# CTRL_MODULE_CORE_PAD register map
Vendor: Texas Instruments
Peripheral module from a debugger description file (folder omap5430_ES2_PUBLIC).
Registers are 32-bit, access per field, reset 0x10F010F unless marked. A register's access mark holds for its fields unless they carry their own. Offsets are as the file gives them; lines under a group give offsets from that group; [hi:lo] are bit positions; {n}, {i} and the like mark numbered series; 'fields as' and 'values as' point back to an identical list; <NAME> marks a mode.

## CTRL_MODULE_CORE_PAD (part 1 of 7)
0x00 CONTROL_CORE_PAD_REVISION ro reset not defined — Control module revision identifier Access conditions. Read: unrestricted, Write: unrestricted
  [31:0] REVISON — IP Revision enum=hl_scheme . enum=legacy_scheme .
0x04 CONTROL_CORE_PAD_HWINFO ro reset 0x0 — Information about the IP module hardware configuration i.e. typically the module HDL generics (if any). Access conditions. Read: unrestricted, Write: unrestricted
  [31:0] IP_HWINFO — IP-module dependent
0x10 CONTROL_CORE_PAD_SYSCONFIG reset 0x8 — Access conditions. Read: unrestricted, Write: unrestricted
  [3:2] IP_SYSCONFIG_IDLEMODE rw — RESERVED (not used).
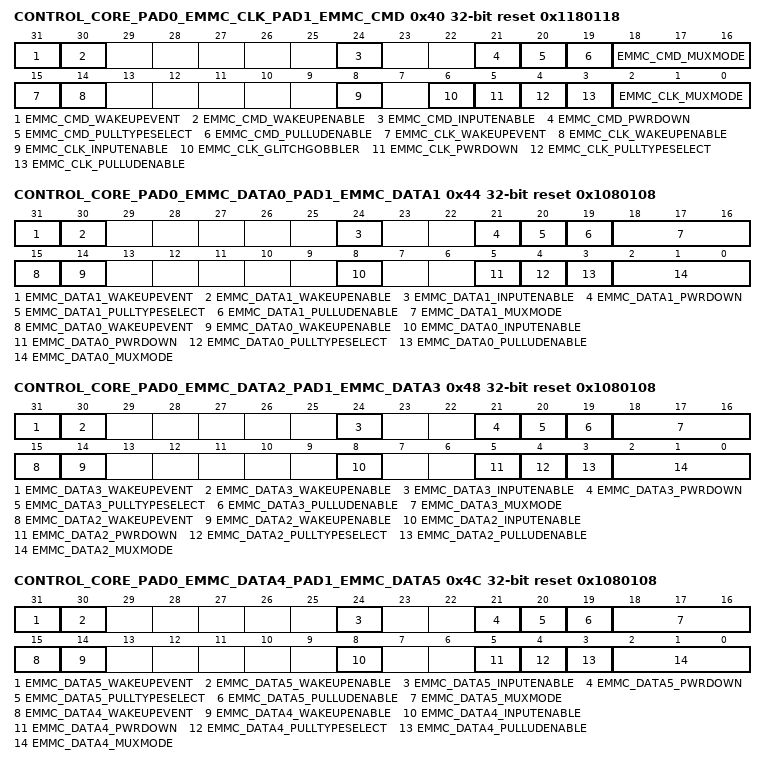
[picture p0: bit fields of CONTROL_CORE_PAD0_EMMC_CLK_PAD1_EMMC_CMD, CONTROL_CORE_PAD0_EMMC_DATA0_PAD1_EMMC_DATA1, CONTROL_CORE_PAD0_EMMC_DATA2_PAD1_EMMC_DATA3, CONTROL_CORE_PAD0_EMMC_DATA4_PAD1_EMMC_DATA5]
0x40 CONTROL_CORE_PAD0_EMMC_CLK_PAD1_EMMC_CMD reset 0x1180118 — Register control for Pads emmc_clk and emmc_cmd Access conditions. Read: unrestricted, Write: unrestricted)
  [31] EMMC_CMD_WAKEUPEVENT ro — Pad_x wake-up event status latched in the IO
    1=WakeUp (A wake-up event occurred); 0=No wake-up event occurred
  [30] EMMC_CMD_WAKEUPENABLE rw — Input pad wake-up enable
    0=DetectLow (wake-up detection is disabled); 1=DetectLowHigh (wake-up detection is enabled)
  [24] EMMC_CMD_INPUTENABLE rw — Input enable value for pad emmc_cmd
    0=InputBufferDisabled (Input buffer of IO cell is disabled); 1=InputBufferEnabled (Input buffer of IO cell is enabled)
  [21] EMMC_CMD_PWRDOWN rw — Power Down setting for pad emmc_cmd
    0=PwrDownDisabled (IO cell power is ON); 1=PwrDownEnabled (IO cell power is OFF)
  [20] EMMC_CMD_PULLTYPESELECT rw — Pull-Up/Down selection for pad emmc_cmd
    0=Pull-Down selected; 1=Pull-Up selected
  [19] EMMC_CMD_PULLUDENABLE rw — Pull-Up/Down enable for pad emmc_cmd
    0=PullDisabled (Pull-Up/Down disabled); 1=PullEnabled (Pull-Up/Down enabled)
  [18:16] EMMC_CMD_MUXMODE rw — Functional multiplexing selection for pad emmc_cmd
    0=SEL_EMMC_CMD (Select emmc_cmd); 7=SEL_SAFE_MODE_CORE1 (Select safe_mode_core1); 6=SEL_GPIO2_47 (Select gpio2_47)
  [15] EMMC_CLK_WAKEUPEVENT ro — Pad_x wake-up event status latched in the IO
    values as EMMC_CMD_WAKEUPEVENT
  [14] EMMC_CLK_WAKEUPENABLE rw — Input pad wake-up enable
    values as EMMC_CMD_WAKEUPENABLE
  [8] EMMC_CLK_INPUTENABLE rw — Input enable value for pad emmc_clk
    values as EMMC_CMD_INPUTENABLE
  [6] EMMC_CLK_GLITCHGOBBLER rw — Glitch Gobbler setting for pad emmc_clk
    0=GlitchGobblerDisabled (IO do not Filter glitch from outside); 1=GlitchGobblerEnabled (IO Filter glitch from outside)
  [5] EMMC_CLK_PWRDOWN rw — Power Down setting for pad emmc_clk
    values as EMMC_CMD_PWRDOWN
  [4] EMMC_CLK_PULLTYPESELECT rw — Pull-Up/Down selection for pad emmc_clk
    0=Pull-Down selected; 1=Pull-Up selected
  [3] EMMC_CLK_PULLUDENABLE rw — Pull-Up/Down enable for pad emmc_clk
    values as EMMC_CMD_PULLUDENABLE
  [2:0] EMMC_CLK_MUXMODE rw — Functional multiplexing selection for pad emmc_clk
    0=SEL_EMMC_CLK (Select emmc_clk); 7=SEL_SAFE_MODE_CORE0 (Select safe_mode_core0); 6=SEL_GPIO2_46 (Select gpio2_46)
0x44 CONTROL_CORE_PAD0_EMMC_DATA0_PAD1_EMMC_DATA1 reset 0x1080108 — Register control for Pads emmc_data0 and emmc_data1 Access conditions. Read: unrestricted, Write: unrestricted
  [31] EMMC_DATA1_WAKEUPEVENT ro — Pad_x wake-up event status latched in the IO
    values as CONTROL_CORE_PAD0_EMMC_CLK_PAD1_EMMC_CMD.EMMC_CMD_WAKEUPEVENT
  [30] EMMC_DATA1_WAKEUPENABLE rw — Input pad wake-up enable
    values as CONTROL_CORE_PAD0_EMMC_CLK_PAD1_EMMC_CMD.EMMC_CMD_WAKEUPENABLE
  [24] EMMC_DATA1_INPUTENABLE rw — Input enable value for pad emmc_data1
    values as CONTROL_CORE_PAD0_EMMC_CLK_PAD1_EMMC_CMD.EMMC_CMD_INPUTENABLE
  [21] EMMC_DATA1_PWRDOWN rw — Power Down setting for pad emmc_data1
    values as CONTROL_CORE_PAD0_EMMC_CLK_PAD1_EMMC_CMD.EMMC_CMD_PWRDOWN
  [20] EMMC_DATA1_PULLTYPESELECT rw — Pull-Up/Down selection for pad emmc_data1
    0=Pull-Down selected; 1=Pull-Up selected
  [19] EMMC_DATA1_PULLUDENABLE rw — Pull-Up/Down enable for pad emmc_data1
    values as CONTROL_CORE_PAD0_EMMC_CLK_PAD1_EMMC_CMD.EMMC_CMD_PULLUDENABLE
  [18:16] EMMC_DATA1_MUXMODE rw — Functional multiplexing selection for pad emmc_data1
    0=SEL_EMMC_DATA1 (Select emmc_data1); 7=SEL_SAFE_MODE_CORE3 (Select safe_mode_core3); 6=SEL_GPIO2_49 (Select gpio2_49)
  [15] EMMC_DATA0_WAKEUPEVENT ro — Pad_x wake-up event status latched in the IO
    values as CONTROL_CORE_PAD0_EMMC_CLK_PAD1_EMMC_CMD.EMMC_CMD_WAKEUPEVENT
  [14] EMMC_DATA0_WAKEUPENABLE rw — Input pad wake-up enable
    values as CONTROL_CORE_PAD0_EMMC_CLK_PAD1_EMMC_CMD.EMMC_CMD_WAKEUPENABLE
  [8] EMMC_DATA0_INPUTENABLE rw — Input enable value for pad emmc_data0
    values as CONTROL_CORE_PAD0_EMMC_CLK_PAD1_EMMC_CMD.EMMC_CMD_INPUTENABLE
  [5] EMMC_DATA0_PWRDOWN rw — Power Down setting for pad emmc_data0
    values as CONTROL_CORE_PAD0_EMMC_CLK_PAD1_EMMC_CMD.EMMC_CMD_PWRDOWN
  [4] EMMC_DATA0_PULLTYPESELECT rw — Pull-Up/Down selection for pad emmc_data0
    0=Pull-Down selected; 1=Pull-Up selected
  [3] EMMC_DATA0_PULLUDENABLE rw — Pull-Up/Down enable for pad emmc_data0
    values as CONTROL_CORE_PAD0_EMMC_CLK_PAD1_EMMC_CMD.EMMC_CMD_PULLUDENABLE
  [2:0] EMMC_DATA0_MUXMODE rw — Functional multiplexing selection for pad emmc_data0
    0=SEL_EMMC_DATA0 (Select emmc_data0); 7=SEL_SAFE_MODE_CORE2 (Select safe_mode_core2); 6=SEL_GPIO2_48 (Select gpio2_48)
0x48 CONTROL_CORE_PAD0_EMMC_DATA2_PAD1_EMMC_DATA3 reset 0x1080108 — Register control for Pads emmc_data2 and emmc_data3 Access conditions. Read: unrestricted, Write: unrestricted
  [31] EMMC_DATA3_WAKEUPEVENT ro — Pad_x wake-up event status latched in the IO
    values as CONTROL_CORE_PAD0_EMMC_CLK_PAD1_EMMC_CMD.EMMC_CMD_WAKEUPEVENT
  [30] EMMC_DATA3_WAKEUPENABLE rw — Input pad wake-up enable
    values as CONTROL_CORE_PAD0_EMMC_CLK_PAD1_EMMC_CMD.EMMC_CMD_WAKEUPENABLE
  [24] EMMC_DATA3_INPUTENABLE rw — Input enable value for pad emmc_data3
    values as CONTROL_CORE_PAD0_EMMC_CLK_PAD1_EMMC_CMD.EMMC_CMD_INPUTENABLE
  [21] EMMC_DATA3_PWRDOWN rw — Power Down setting for pad emmc_data3
    values as CONTROL_CORE_PAD0_EMMC_CLK_PAD1_EMMC_CMD.EMMC_CMD_PWRDOWN
  [20] EMMC_DATA3_PULLTYPESELECT rw — Pull-Up/Down selection for pad emmc_data3
    0=Pull-Down selected; 1=Pull-Up selected
  [19] EMMC_DATA3_PULLUDENABLE rw — Pull-Up/Down enable for pad emmc_data3
    values as CONTROL_CORE_PAD0_EMMC_CLK_PAD1_EMMC_CMD.EMMC_CMD_PULLUDENABLE
  [18:16] EMMC_DATA3_MUXMODE rw — Functional multiplexing selection for pad emmc_data3
    0=SEL_EMMC_DATA3 (Select emmc_data3); 7=SEL_SAFE_MODE_CORE5 (Select safe_mode_core5); 6=SEL_GPIO2_51 (Select gpio2_51)
  [15] EMMC_DATA2_WAKEUPEVENT ro — Pad_x wake-up event status latched in the IO
    values as CONTROL_CORE_PAD0_EMMC_CLK_PAD1_EMMC_CMD.EMMC_CMD_WAKEUPEVENT
  [14] EMMC_DATA2_WAKEUPENABLE rw — Input pad wake-up enable
    values as CONTROL_CORE_PAD0_EMMC_CLK_PAD1_EMMC_CMD.EMMC_CMD_WAKEUPENABLE
  [8] EMMC_DATA2_INPUTENABLE rw — Input enable value for pad emmc_data2
    values as CONTROL_CORE_PAD0_EMMC_CLK_PAD1_EMMC_CMD.EMMC_CMD_INPUTENABLE
  [5] EMMC_DATA2_PWRDOWN rw — Power Down setting for pad emmc_data2
    values as CONTROL_CORE_PAD0_EMMC_CLK_PAD1_EMMC_CMD.EMMC_CMD_PWRDOWN
  [4] EMMC_DATA2_PULLTYPESELECT rw — Pull-Up/Down selection for pad emmc_data2
    0=Pull-Down selected; 1=Pull-Up selected
  [3] EMMC_DATA2_PULLUDENABLE rw — Pull-Up/Down enable for pad emmc_data2
    values as CONTROL_CORE_PAD0_EMMC_CLK_PAD1_EMMC_CMD.EMMC_CMD_PULLUDENABLE
  [2:0] EMMC_DATA2_MUXMODE rw — Functional multiplexing selection for pad emmc_data2
    0=SEL_EMMC_DATA2 (Select emmc_data2); 7=SEL_SAFE_MODE_CORE4 (Select safe_mode_core4); 6=SEL_GPIO2_50 (Select gpio2_50)
0x4C CONTROL_CORE_PAD0_EMMC_DATA4_PAD1_EMMC_DATA5 reset 0x1080108 — Register control for Pads emmc_data4 and emmc_data5 Access conditions. Read: unrestricted, Write: unrestricted
  [31] EMMC_DATA5_WAKEUPEVENT ro — Pad_x wake-up event status latched in the IO
    values as CONTROL_CORE_PAD0_EMMC_CLK_PAD1_EMMC_CMD.EMMC_CMD_WAKEUPEVENT
  [30] EMMC_DATA5_WAKEUPENABLE rw — Input pad wake-up enable
    values as CONTROL_CORE_PAD0_EMMC_CLK_PAD1_EMMC_CMD.EMMC_CMD_WAKEUPENABLE
  [24] EMMC_DATA5_INPUTENABLE rw — Input enable value for pad emmc_data5
    values as CONTROL_CORE_PAD0_EMMC_CLK_PAD1_EMMC_CMD.EMMC_CMD_INPUTENABLE
  [21] EMMC_DATA5_PWRDOWN rw — Power Down setting for pad emmc_data5
    values as CONTROL_CORE_PAD0_EMMC_CLK_PAD1_EMMC_CMD.EMMC_CMD_PWRDOWN
  [20] EMMC_DATA5_PULLTYPESELECT rw — Pull-Up/Down selection for pad emmc_data5
    0=Pull-Down selected; 1=Pull-Up selected
  [19] EMMC_DATA5_PULLUDENABLE rw — Pull-Up/Down enable for pad emmc_data5
    values as CONTROL_CORE_PAD0_EMMC_CLK_PAD1_EMMC_CMD.EMMC_CMD_PULLUDENABLE
  [18:16] EMMC_DATA5_MUXMODE rw — Functional multiplexing selection for pad emmc_data5
    0=SEL_EMMC_DATA5 (Select emmc_data5); 7=SEL_SAFE_MODE_CORE7 (Select safe_mode_core7); 6=SEL_GPIO2_53 (Select gpio2_53)
  [15] EMMC_DATA4_WAKEUPEVENT ro — Pad_x wake-up event status latched in the IO
    values as CONTROL_CORE_PAD0_EMMC_CLK_PAD1_EMMC_CMD.EMMC_CMD_WAKEUPEVENT
  [14] EMMC_DATA4_WAKEUPENABLE rw — Input pad wake-up enable
    values as CONTROL_CORE_PAD0_EMMC_CLK_PAD1_EMMC_CMD.EMMC_CMD_WAKEUPENABLE
  [8] EMMC_DATA4_INPUTENABLE rw — Input enable value for pad emmc_data4
    values as CONTROL_CORE_PAD0_EMMC_CLK_PAD1_EMMC_CMD.EMMC_CMD_INPUTENABLE
  [5] EMMC_DATA4_PWRDOWN rw — Power Down setting for pad emmc_data4
    values as CONTROL_CORE_PAD0_EMMC_CLK_PAD1_EMMC_CMD.EMMC_CMD_PWRDOWN
  [4] EMMC_DATA4_PULLTYPESELECT rw — Pull-Up/Down selection for pad emmc_data4
    0=Pull-Down selected; 1=Pull-Up selected
  [3] EMMC_DATA4_PULLUDENABLE rw — Pull-Up/Down enable for pad emmc_data4
    values as CONTROL_CORE_PAD0_EMMC_CLK_PAD1_EMMC_CMD.EMMC_CMD_PULLUDENABLE
  [2:0] EMMC_DATA4_MUXMODE rw — Functional multiplexing selection for pad emmc_data4
    0=SEL_EMMC_DATA4 (Select emmc_data4); 7=SEL_SAFE_MODE_CORE6 (Select safe_mode_core6); 6=SEL_GPIO2_52 (Select gpio2_52)
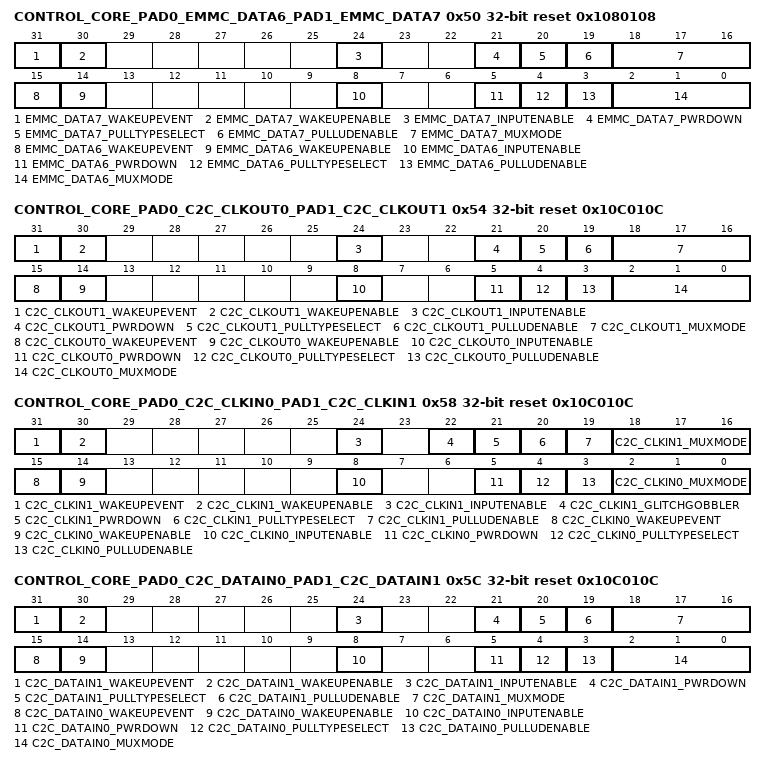
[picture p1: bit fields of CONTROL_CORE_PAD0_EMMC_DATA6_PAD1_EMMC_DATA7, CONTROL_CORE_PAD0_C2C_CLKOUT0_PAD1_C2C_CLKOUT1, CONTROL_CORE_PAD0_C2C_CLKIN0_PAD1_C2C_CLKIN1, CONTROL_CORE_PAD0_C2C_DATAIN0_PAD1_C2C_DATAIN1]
0x50 CONTROL_CORE_PAD0_EMMC_DATA6_PAD1_EMMC_DATA7 reset 0x1080108 — Register control for Pads emmc_data6 and emmc_data7 Access conditions. Read: unrestricted, Write: unrestricted
  [31] EMMC_DATA7_WAKEUPEVENT ro — Pad_x wake-up event status latched in the IO
    values as CONTROL_CORE_PAD0_EMMC_CLK_PAD1_EMMC_CMD.EMMC_CMD_WAKEUPEVENT
  [30] EMMC_DATA7_WAKEUPENABLE rw — Input pad wake-up enable
    values as CONTROL_CORE_PAD0_EMMC_CLK_PAD1_EMMC_CMD.EMMC_CMD_WAKEUPENABLE
  [24] EMMC_DATA7_INPUTENABLE rw — Input enable value for pad emmc_data7
    values as CONTROL_CORE_PAD0_EMMC_CLK_PAD1_EMMC_CMD.EMMC_CMD_INPUTENABLE
  [21] EMMC_DATA7_PWRDOWN rw — Power Down setting for pad emmc_data7
    values as CONTROL_CORE_PAD0_EMMC_CLK_PAD1_EMMC_CMD.EMMC_CMD_PWRDOWN
  [20] EMMC_DATA7_PULLTYPESELECT rw — Pull-Up/Down selection for pad emmc_data7
    0=Pull-Down selected; 1=Pull-Up selected
  [19] EMMC_DATA7_PULLUDENABLE rw — Pull-Up/Down enable for pad emmc_data7
    values as CONTROL_CORE_PAD0_EMMC_CLK_PAD1_EMMC_CMD.EMMC_CMD_PULLUDENABLE
  [18:16] EMMC_DATA7_MUXMODE rw — Functional multiplexing selection for pad emmc_data7
    0=SEL_EMMC_DATA7 (Select emmc_data7); 7=SEL_SAFE_MODE_CORE9 (Select safe_mode_core9); 6=SEL_GPIO2_55 (Select gpio2_55)
  [15] EMMC_DATA6_WAKEUPEVENT ro — Pad_x wake-up event status latched in the IO
    values as CONTROL_CORE_PAD0_EMMC_CLK_PAD1_EMMC_CMD.EMMC_CMD_WAKEUPEVENT
  [14] EMMC_DATA6_WAKEUPENABLE rw — Input pad wake-up enable
    values as CONTROL_CORE_PAD0_EMMC_CLK_PAD1_EMMC_CMD.EMMC_CMD_WAKEUPENABLE
  [8] EMMC_DATA6_INPUTENABLE rw — Input enable value for pad emmc_data6
    values as CONTROL_CORE_PAD0_EMMC_CLK_PAD1_EMMC_CMD.EMMC_CMD_INPUTENABLE
  [5] EMMC_DATA6_PWRDOWN rw — Power Down setting for pad emmc_data6
    values as CONTROL_CORE_PAD0_EMMC_CLK_PAD1_EMMC_CMD.EMMC_CMD_PWRDOWN
  [4] EMMC_DATA6_PULLTYPESELECT rw — Pull-Up/Down selection for pad emmc_data6
    0=Pull-Down selected; 1=Pull-Up selected
  [3] EMMC_DATA6_PULLUDENABLE rw — Pull-Up/Down enable for pad emmc_data6
    values as CONTROL_CORE_PAD0_EMMC_CLK_PAD1_EMMC_CMD.EMMC_CMD_PULLUDENABLE
  [2:0] EMMC_DATA6_MUXMODE rw — Functional multiplexing selection for pad emmc_data6
    0=SEL_EMMC_DATA6 (Select emmc_data6); 7=SEL_SAFE_MODE_CORE8 (Select safe_mode_core8); 6=SEL_GPIO2_54 (Select gpio2_54)
0x54 CONTROL_CORE_PAD0_C2C_CLKOUT0_PAD1_C2C_CLKOUT1 reset 0x10C010C — Register control for Pads c2c_clkout0 and c2c_clkout1 Access conditions. Read: unrestricted, Write: unrestricted
  [31] C2C_CLKOUT1_WAKEUPEVENT ro — Pad_x wake-up event status latched in the IO
    values as CONTROL_CORE_PAD0_EMMC_CLK_PAD1_EMMC_CMD.EMMC_CMD_WAKEUPEVENT
  [30] C2C_CLKOUT1_WAKEUPENABLE rw — Input pad wake-up enable
    values as CONTROL_CORE_PAD0_EMMC_CLK_PAD1_EMMC_CMD.EMMC_CMD_WAKEUPENABLE
  [24] C2C_CLKOUT1_INPUTENABLE rw — Input enable value for pad c2c_clkout1
    values as CONTROL_CORE_PAD0_EMMC_CLK_PAD1_EMMC_CMD.EMMC_CMD_INPUTENABLE
  [21] C2C_CLKOUT1_PWRDOWN rw — Power Down setting for pad c2c_clkout1
    values as CONTROL_CORE_PAD0_EMMC_CLK_PAD1_EMMC_CMD.EMMC_CMD_PWRDOWN
  [20] C2C_CLKOUT1_PULLTYPESELECT rw — Pull-Up/Down selection for pad c2c_clkout1
    0=Pull-Down selected; 1=Pull-Up selected
  [19] C2C_CLKOUT1_PULLUDENABLE rw — Pull-Up/Down enable for pad c2c_clkout1
    values as CONTROL_CORE_PAD0_EMMC_CLK_PAD1_EMMC_CMD.EMMC_CMD_PULLUDENABLE
  [18:16] C2C_CLKOUT1_MUXMODE rw — Functional multiplexing selection for pad c2c_clkout1
    0=SEL_C2C_CLKOUT1 (Reserved); 3=SEL_KBD_COL8 (Select kbd_col8); 7=SEL_SAFE_MODE_CORE21 (Select safe_mode_core21); 4=SEL_GPMC_NBE0_CLE (Select gpmc_nbe0_cle); 6=SEL_GPIO2_34 (Select gpio2_34)
  [15] C2C_CLKOUT0_WAKEUPEVENT ro — Pad_x wake-up event status latched in the IO
    values as CONTROL_CORE_PAD0_EMMC_CLK_PAD1_EMMC_CMD.EMMC_CMD_WAKEUPEVENT
  [14] C2C_CLKOUT0_WAKEUPENABLE rw — Input pad wake-up enable
    values as CONTROL_CORE_PAD0_EMMC_CLK_PAD1_EMMC_CMD.EMMC_CMD_WAKEUPENABLE
  [8] C2C_CLKOUT0_INPUTENABLE rw — Input enable value for pad c2c_clkout0
    values as CONTROL_CORE_PAD0_EMMC_CLK_PAD1_EMMC_CMD.EMMC_CMD_INPUTENABLE
  [5] C2C_CLKOUT0_PWRDOWN rw — Power Down setting for pad c2c_clkout0
    values as CONTROL_CORE_PAD0_EMMC_CLK_PAD1_EMMC_CMD.EMMC_CMD_PWRDOWN
  [4] C2C_CLKOUT0_PULLTYPESELECT rw — Pull-Up/Down selection for pad c2c_clkout0
    0=Pull-Down selected; 1=Pull-Up selected
  [3] C2C_CLKOUT0_PULLUDENABLE rw — Pull-Up/Down enable for pad c2c_clkout0
    values as CONTROL_CORE_PAD0_EMMC_CLK_PAD1_EMMC_CMD.EMMC_CMD_PULLUDENABLE
  [2:0] C2C_CLKOUT0_MUXMODE rw — Functional multiplexing selection for pad c2c_clkout0
    0=SEL_C2C_CLKOUT0 (Reserved); 4=SEL_GPMC_NADV_ALE (Select gpmc_nadv_ale); 7=SEL_SAFE_MODE_CORE20 (Select safe_mode_core20); 6=SEL_GPIO2_33 (Select gpio2_33)
0x58 CONTROL_CORE_PAD0_C2C_CLKIN0_PAD1_C2C_CLKIN1 reset 0x10C010C — Register control for Pads c2c_clkin0 and c2c_clkin1 Access conditions. Read: unrestricted, Write: unrestricted
  [31] C2C_CLKIN1_WAKEUPEVENT ro — Pad_x wake-up event status latched in the IO
    values as CONTROL_CORE_PAD0_EMMC_CLK_PAD1_EMMC_CMD.EMMC_CMD_WAKEUPEVENT
  [30] C2C_CLKIN1_WAKEUPENABLE rw — Input pad wake-up enable
    values as CONTROL_CORE_PAD0_EMMC_CLK_PAD1_EMMC_CMD.EMMC_CMD_WAKEUPENABLE
  [24] C2C_CLKIN1_INPUTENABLE rw — Input enable value for pad c2c_clkin1
    values as CONTROL_CORE_PAD0_EMMC_CLK_PAD1_EMMC_CMD.EMMC_CMD_INPUTENABLE
  [22] C2C_CLKIN1_GLITCHGOBBLER rw — Glitch Gobbler setting for pad c2c_clkin1
    values as CONTROL_CORE_PAD0_EMMC_CLK_PAD1_EMMC_CMD.EMMC_CLK_GLITCHGOBBLER
  [21] C2C_CLKIN1_PWRDOWN rw — Power Down setting for pad c2c_clkin1
    values as CONTROL_CORE_PAD0_EMMC_CLK_PAD1_EMMC_CMD.EMMC_CMD_PWRDOWN
  [20] C2C_CLKIN1_PULLTYPESELECT rw — Pull-Up/Down selection for pad c2c_clkin1
    0=Pull-Down selected; 1=Pull-Up selected
  [19] C2C_CLKIN1_PULLUDENABLE rw — Pull-Up/Down enable for pad c2c_clkin1
    values as CONTROL_CORE_PAD0_EMMC_CLK_PAD1_EMMC_CMD.EMMC_CMD_PULLUDENABLE
  [18:16] C2C_CLKIN1_MUXMODE rw — Functional multiplexing selection for pad c2c_clkin1
    0=SEL_C2C_CLKIN1 (Reserved); 3=SEL_KBD_ROW8 (Select kbd_row8); 7=SEL_SAFE_MODE_CORE18 (Select safe_mode_core18); 4=SEL_GPMC_CLK (Select gpmc_clk); 6=SEL_GPIO2_36 (Select gpio2_36)
  [15] C2C_CLKIN0_WAKEUPEVENT ro — Pad_x wake-up event status latched in the IO
    values as CONTROL_CORE_PAD0_EMMC_CLK_PAD1_EMMC_CMD.EMMC_CMD_WAKEUPEVENT
  [14] C2C_CLKIN0_WAKEUPENABLE rw — Input pad wake-up enable
    values as CONTROL_CORE_PAD0_EMMC_CLK_PAD1_EMMC_CMD.EMMC_CMD_WAKEUPENABLE
  [8] C2C_CLKIN0_INPUTENABLE rw — Input enable value for pad c2c_clkin0
    values as CONTROL_CORE_PAD0_EMMC_CLK_PAD1_EMMC_CMD.EMMC_CMD_INPUTENABLE
  [5] C2C_CLKIN0_PWRDOWN rw — Power Down setting for pad c2c_clkin0
    values as CONTROL_CORE_PAD0_EMMC_CLK_PAD1_EMMC_CMD.EMMC_CMD_PWRDOWN
  [4] C2C_CLKIN0_PULLTYPESELECT rw — Pull-Up/Down selection for pad c2c_clkin0
    0=Pull-Down selected; 1=Pull-Up selected
  [3] C2C_CLKIN0_PULLUDENABLE rw — Pull-Up/Down enable for pad c2c_clkin0
    values as CONTROL_CORE_PAD0_EMMC_CLK_PAD1_EMMC_CMD.EMMC_CMD_PULLUDENABLE
  [2:0] C2C_CLKIN0_MUXMODE rw — Functional multiplexing selection for pad c2c_clkin0
    0=SEL_C2C_CLKIN0 (Reserved); 6=SEL_GPIO2_35 (Select gpio2_35); 4=SEL_GPMC_NWP (Select gpmc_nwp); 7=SEL_SAFE_MODE_CORE19 (Select safe_mode_core19); 5=SEL_GPMC_NBE1 (Select gpmc_nbe1)
0x5C CONTROL_CORE_PAD0_C2C_DATAIN0_PAD1_C2C_DATAIN1 reset 0x10C010C — Register control for Pads c2c_datain0 and c2c_datain1 Access conditions. Read: unrestricted, Write: unrestricted
  [31] C2C_DATAIN1_WAKEUPEVENT ro — Pad_x wake-up event status latched in the IO
    values as CONTROL_CORE_PAD0_EMMC_CLK_PAD1_EMMC_CMD.EMMC_CMD_WAKEUPEVENT
  [30] C2C_DATAIN1_WAKEUPENABLE rw — Input pad wake-up enable
    values as CONTROL_CORE_PAD0_EMMC_CLK_PAD1_EMMC_CMD.EMMC_CMD_WAKEUPENABLE
  [24] C2C_DATAIN1_INPUTENABLE rw — Input enable value for pad c2c_datain1
    values as CONTROL_CORE_PAD0_EMMC_CLK_PAD1_EMMC_CMD.EMMC_CMD_INPUTENABLE
  [21] C2C_DATAIN1_PWRDOWN rw — Power Down setting for pad c2c_datain1
    values as CONTROL_CORE_PAD0_EMMC_CLK_PAD1_EMMC_CMD.EMMC_CMD_PWRDOWN
  [20] C2C_DATAIN1_PULLTYPESELECT rw — Pull-Up/Down selection for pad c2c_datain1
    0=Pull-Down selected; 1=Pull-Up selected
  [19] C2C_DATAIN1_PULLUDENABLE rw — Pull-Up/Down enable for pad c2c_datain1
    values as CONTROL_CORE_PAD0_EMMC_CLK_PAD1_EMMC_CMD.EMMC_CMD_PULLUDENABLE
  [18:16] C2C_DATAIN1_MUXMODE rw — Functional multiplexing selection for pad c2c_datain1
    0=SEL_C2C_DATAIN1 (Reserved); 3=SEL_KBD_ROW1 (Select kbd_row1); 7=SEL_SAFE_MODE_CORE11 (Select safe_mode_core11); 4=SEL_GPMC_AD1 (Select gpmc_ad1); 6=SEL_GPIO2_38 (Select gpio2_38)
  [15] C2C_DATAIN0_WAKEUPEVENT ro — Pad_x wake-up event status latched in the IO
    values as CONTROL_CORE_PAD0_EMMC_CLK_PAD1_EMMC_CMD.EMMC_CMD_WAKEUPEVENT
  [14] C2C_DATAIN0_WAKEUPENABLE rw — Input pad wake-up enable
    values as CONTROL_CORE_PAD0_EMMC_CLK_PAD1_EMMC_CMD.EMMC_CMD_WAKEUPENABLE
  [8] C2C_DATAIN0_INPUTENABLE rw — Input enable value for pad c2c_datain0
    values as CONTROL_CORE_PAD0_EMMC_CLK_PAD1_EMMC_CMD.EMMC_CMD_INPUTENABLE
  [5] C2C_DATAIN0_PWRDOWN rw — Power Down setting for pad c2c_datain0
    values as CONTROL_CORE_PAD0_EMMC_CLK_PAD1_EMMC_CMD.EMMC_CMD_PWRDOWN
  [4] C2C_DATAIN0_PULLTYPESELECT rw — Pull-Up/Down selection for pad c2c_datain0
    0=Pull-Down selected; 1=Pull-Up selected
  [3] C2C_DATAIN0_PULLUDENABLE rw — Pull-Up/Down enable for pad c2c_datain0
    values as CONTROL_CORE_PAD0_EMMC_CLK_PAD1_EMMC_CMD.EMMC_CMD_PULLUDENABLE
  [2:0] C2C_DATAIN0_MUXMODE rw — Functional multiplexing selection for pad c2c_datain0
    0=SEL_C2C_DATAIN0 (Reserved); 3=SEL_KBD_ROW0 (Select kbd_row0); 7=SEL_SAFE_MODE_CORE10 (Select safe_mode_core10); 4=SEL_GPMC_AD0 (Select gpmc_ad0); 6=SEL_GPIO2_37 (Select gpio2_37)
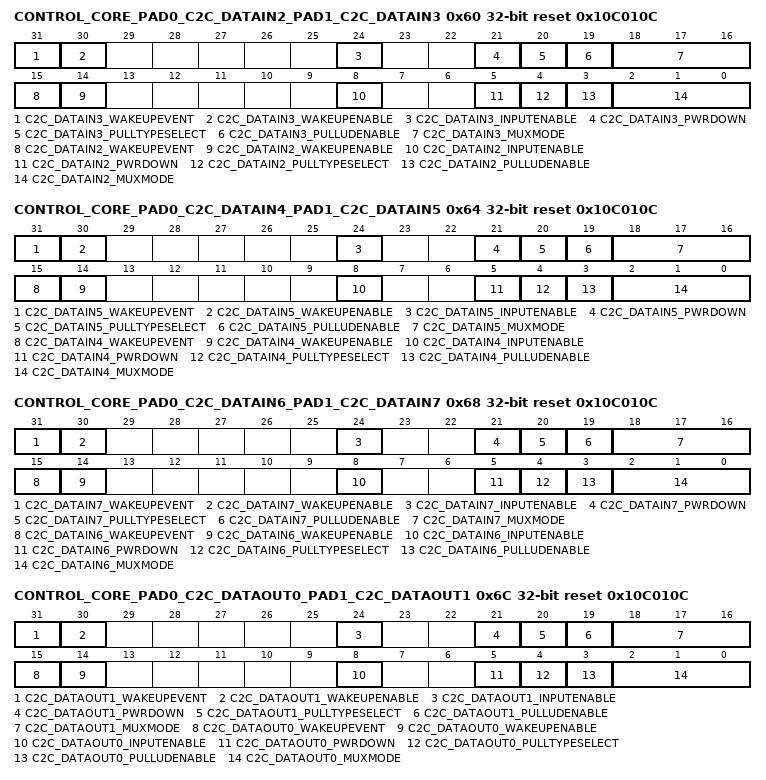
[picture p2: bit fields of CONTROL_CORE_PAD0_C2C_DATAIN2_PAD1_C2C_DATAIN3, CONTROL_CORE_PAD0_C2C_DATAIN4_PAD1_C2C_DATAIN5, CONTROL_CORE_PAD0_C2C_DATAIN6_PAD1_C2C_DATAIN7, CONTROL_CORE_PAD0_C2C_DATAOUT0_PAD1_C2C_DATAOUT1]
0x60 CONTROL_CORE_PAD0_C2C_DATAIN2_PAD1_C2C_DATAIN3 reset 0x10C010C — Register control for Pads c2c_datain2 and c2c_datain3 Access conditions. Read: unrestricted, Write: unrestricted
  [31] C2C_DATAIN3_WAKEUPEVENT ro — Pad_x wake-up event status latched in the IO
    values as CONTROL_CORE_PAD0_EMMC_CLK_PAD1_EMMC_CMD.EMMC_CMD_WAKEUPEVENT
  [30] C2C_DATAIN3_WAKEUPENABLE rw — Input pad wake-up enable
    values as CONTROL_CORE_PAD0_EMMC_CLK_PAD1_EMMC_CMD.EMMC_CMD_WAKEUPENABLE
  [24] C2C_DATAIN3_INPUTENABLE rw — Input enable value for pad c2c_datain3
    values as CONTROL_CORE_PAD0_EMMC_CLK_PAD1_EMMC_CMD.EMMC_CMD_INPUTENABLE
  [21] C2C_DATAIN3_PWRDOWN rw — Power Down setting for pad c2c_datain3
    values as CONTROL_CORE_PAD0_EMMC_CLK_PAD1_EMMC_CMD.EMMC_CMD_PWRDOWN
  [20] C2C_DATAIN3_PULLTYPESELECT rw — Pull-Up/Down selection for pad c2c_datain3
    0=Pull-Down selected; 1=Pull-Up selected
  [19] C2C_DATAIN3_PULLUDENABLE rw — Pull-Up/Down enable for pad c2c_datain3
    values as CONTROL_CORE_PAD0_EMMC_CLK_PAD1_EMMC_CMD.EMMC_CMD_PULLUDENABLE
  [18:16] C2C_DATAIN3_MUXMODE rw — Functional multiplexing selection for pad c2c_datain3
    0=SEL_C2C_DATAIN3 (Reserved); 3=SEL_KBD_ROW3 (Select kbd_row3); 7=SEL_SAFE_MODE_CORE13 (Select safe_mode_core13); 4=SEL_GPMC_AD3 (Select gpmc_ad3); 6=SEL_GPIO2_40 (Select gpio2_40)
  [15] C2C_DATAIN2_WAKEUPEVENT ro — Pad_x wake-up event status latched in the IO
    values as CONTROL_CORE_PAD0_EMMC_CLK_PAD1_EMMC_CMD.EMMC_CMD_WAKEUPEVENT
  [14] C2C_DATAIN2_WAKEUPENABLE rw — Input pad wake-up enable
    values as CONTROL_CORE_PAD0_EMMC_CLK_PAD1_EMMC_CMD.EMMC_CMD_WAKEUPENABLE
  [8] C2C_DATAIN2_INPUTENABLE rw — Input enable value for pad c2c_datain2
    values as CONTROL_CORE_PAD0_EMMC_CLK_PAD1_EMMC_CMD.EMMC_CMD_INPUTENABLE
  [5] C2C_DATAIN2_PWRDOWN rw — Power Down setting for pad c2c_datain2
    values as CONTROL_CORE_PAD0_EMMC_CLK_PAD1_EMMC_CMD.EMMC_CMD_PWRDOWN
  [4] C2C_DATAIN2_PULLTYPESELECT rw — Pull-Up/Down selection for pad c2c_datain2
    0=Pull-Down selected; 1=Pull-Up selected
  [3] C2C_DATAIN2_PULLUDENABLE rw — Pull-Up/Down enable for pad c2c_datain2
    values as CONTROL_CORE_PAD0_EMMC_CLK_PAD1_EMMC_CMD.EMMC_CMD_PULLUDENABLE
  [2:0] C2C_DATAIN2_MUXMODE rw — Functional multiplexing selection for pad c2c_datain2
    0=SEL_C2C_DATAIN2 (Reserved); 3=SEL_KBD_ROW2 (Select kbd_row2); 7=SEL_SAFE_MODE_CORE12 (Select safe_mode_core12); 4=SEL_GPMC_AD2 (Select gpmc_ad2); 6=SEL_GPIO2_39 (Select gpio2_39)
0x64 CONTROL_CORE_PAD0_C2C_DATAIN4_PAD1_C2C_DATAIN5 reset 0x10C010C — Register control for Pads c2c_datain4 and c2c_datain5 Access conditions. Read: unrestricted, Write: unrestricted
  [31] C2C_DATAIN5_WAKEUPEVENT ro — Pad_x wake-up event status latched in the IO
    values as CONTROL_CORE_PAD0_EMMC_CLK_PAD1_EMMC_CMD.EMMC_CMD_WAKEUPEVENT
  [30] C2C_DATAIN5_WAKEUPENABLE rw — Input pad wake-up enable
    values as CONTROL_CORE_PAD0_EMMC_CLK_PAD1_EMMC_CMD.EMMC_CMD_WAKEUPENABLE
  [24] C2C_DATAIN5_INPUTENABLE rw — Input enable value for pad c2c_datain5
    values as CONTROL_CORE_PAD0_EMMC_CLK_PAD1_EMMC_CMD.EMMC_CMD_INPUTENABLE
  [21] C2C_DATAIN5_PWRDOWN rw — Power Down setting for pad c2c_datain5
    values as CONTROL_CORE_PAD0_EMMC_CLK_PAD1_EMMC_CMD.EMMC_CMD_PWRDOWN
  [20] C2C_DATAIN5_PULLTYPESELECT rw — Pull-Up/Down selection for pad c2c_datain5
    0=Pull-Down selected; 1=Pull-Up selected
  [19] C2C_DATAIN5_PULLUDENABLE rw — Pull-Up/Down enable for pad c2c_datain5
    values as CONTROL_CORE_PAD0_EMMC_CLK_PAD1_EMMC_CMD.EMMC_CMD_PULLUDENABLE
  [18:16] C2C_DATAIN5_MUXMODE rw — Functional multiplexing selection for pad c2c_datain5
    0=SEL_C2C_DATAIN5 (Reserved); 3=SEL_KBD_ROW5 (Select kbd_row5); 7=SEL_SAFE_MODE_CORE15 (Select safe_mode_core15); 4=SEL_GPMC_AD5 (Select gpmc_ad5); 6=SEL_GPIO2_42 (Select gpio2_42)
  [15] C2C_DATAIN4_WAKEUPEVENT ro — Pad_x wake-up event status latched in the IO
    values as CONTROL_CORE_PAD0_EMMC_CLK_PAD1_EMMC_CMD.EMMC_CMD_WAKEUPEVENT
  [14] C2C_DATAIN4_WAKEUPENABLE rw — Input pad wake-up enable
    values as CONTROL_CORE_PAD0_EMMC_CLK_PAD1_EMMC_CMD.EMMC_CMD_WAKEUPENABLE
  [8] C2C_DATAIN4_INPUTENABLE rw — Input enable value for pad c2c_datain4
    values as CONTROL_CORE_PAD0_EMMC_CLK_PAD1_EMMC_CMD.EMMC_CMD_INPUTENABLE
  [5] C2C_DATAIN4_PWRDOWN rw — Power Down setting for pad c2c_datain4
    values as CONTROL_CORE_PAD0_EMMC_CLK_PAD1_EMMC_CMD.EMMC_CMD_PWRDOWN
  [4] C2C_DATAIN4_PULLTYPESELECT rw — Pull-Up/Down selection for pad c2c_datain4
    0=Pull-Down selected; 1=Pull-Up selected
  [3] C2C_DATAIN4_PULLUDENABLE rw — Pull-Up/Down enable for pad c2c_datain4
    values as CONTROL_CORE_PAD0_EMMC_CLK_PAD1_EMMC_CMD.EMMC_CMD_PULLUDENABLE
  [2:0] C2C_DATAIN4_MUXMODE rw — Functional multiplexing selection for pad c2c_datain4
    0=SEL_C2C_DATAIN4 (Reserved); 3=SEL_KBD_ROW4 (Select kbd_row4); 7=SEL_SAFE_MODE_CORE14 (Select safe_mode_core14); 4=SEL_GPMC_AD4 (Select gpmc_ad4); 6=SEL_GPIO2_41 (Select gpio2_41)
0x68 CONTROL_CORE_PAD0_C2C_DATAIN6_PAD1_C2C_DATAIN7 reset 0x10C010C — Register control for Pads c2c_datain6 and c2c_datain7 Access conditions. Read: unrestricted, Write: unrestricted
  [31] C2C_DATAIN7_WAKEUPEVENT ro — Pad_x wake-up event status latched in the IO
    values as CONTROL_CORE_PAD0_EMMC_CLK_PAD1_EMMC_CMD.EMMC_CMD_WAKEUPEVENT
  [30] C2C_DATAIN7_WAKEUPENABLE rw — Input pad wake-up enable
    values as CONTROL_CORE_PAD0_EMMC_CLK_PAD1_EMMC_CMD.EMMC_CMD_WAKEUPENABLE
  [24] C2C_DATAIN7_INPUTENABLE rw — Input enable value for pad c2c_datain7
    values as CONTROL_CORE_PAD0_EMMC_CLK_PAD1_EMMC_CMD.EMMC_CMD_INPUTENABLE
  [21] C2C_DATAIN7_PWRDOWN rw — Power Down setting for pad c2c_datain7
    values as CONTROL_CORE_PAD0_EMMC_CLK_PAD1_EMMC_CMD.EMMC_CMD_PWRDOWN
  [20] C2C_DATAIN7_PULLTYPESELECT rw — Pull-Up/Down selection for pad c2c_datain7
    0=Pull-Down selected; 1=Pull-Up selected
  [19] C2C_DATAIN7_PULLUDENABLE rw — Pull-Up/Down enable for pad c2c_datain7
    values as CONTROL_CORE_PAD0_EMMC_CLK_PAD1_EMMC_CMD.EMMC_CMD_PULLUDENABLE
  [18:16] C2C_DATAIN7_MUXMODE rw — Functional multiplexing selection for pad c2c_datain7
    0=SEL_C2C_DATAIN7 (Reserved); 3=SEL_KBD_ROW7 (Select kbd_row7); 7=SEL_SAFE_MODE_CORE17 (Select safe_mode_core17); 4=SEL_GPMC_AD7 (Select gpmc_ad7); 6=SEL_GPIO2_44 (Select gpio2_44)
  [15] C2C_DATAIN6_WAKEUPEVENT ro — Pad_x wake-up event status latched in the IO
    values as CONTROL_CORE_PAD0_EMMC_CLK_PAD1_EMMC_CMD.EMMC_CMD_WAKEUPEVENT
  [14] C2C_DATAIN6_WAKEUPENABLE rw — Input pad wake-up enable
    values as CONTROL_CORE_PAD0_EMMC_CLK_PAD1_EMMC_CMD.EMMC_CMD_WAKEUPENABLE
  [8] C2C_DATAIN6_INPUTENABLE rw — Input enable value for pad c2c_datain6
    values as CONTROL_CORE_PAD0_EMMC_CLK_PAD1_EMMC_CMD.EMMC_CMD_INPUTENABLE
  [5] C2C_DATAIN6_PWRDOWN rw — Power Down setting for pad c2c_datain6
    values as CONTROL_CORE_PAD0_EMMC_CLK_PAD1_EMMC_CMD.EMMC_CMD_PWRDOWN
  [4] C2C_DATAIN6_PULLTYPESELECT rw — Pull-Up/Down selection for pad c2c_datain6
    0=Pull-Down selected; 1=Pull-Up selected
  [3] C2C_DATAIN6_PULLUDENABLE rw — Pull-Up/Down enable for pad c2c_datain6
    values as CONTROL_CORE_PAD0_EMMC_CLK_PAD1_EMMC_CMD.EMMC_CMD_PULLUDENABLE
  [2:0] C2C_DATAIN6_MUXMODE rw — Functional multiplexing selection for pad c2c_datain6
    0=SEL_C2C_DATAIN6 (Reserved); 3=SEL_KBD_ROW6 (Select kbd_row6); 7=SEL_SAFE_MODE_CORE16 (Select safe_mode_core16); 4=SEL_GPMC_AD6 (Select gpmc_ad6); 6=SEL_GPIO2_43 (Select gpio2_43)
0x6C CONTROL_CORE_PAD0_C2C_DATAOUT0_PAD1_C2C_DATAOUT1 reset 0x10C010C — Register control for Pads c2c_dataout0 and c2c_dataout1 Access conditions. Read: unrestricted, Write: unrestricted
  [31] C2C_DATAOUT1_WAKEUPEVENT ro — Pad_x wake-up event status latched in the IO
    values as CONTROL_CORE_PAD0_EMMC_CLK_PAD1_EMMC_CMD.EMMC_CMD_WAKEUPEVENT
  [30] C2C_DATAOUT1_WAKEUPENABLE rw — Input pad wake-up enable
    values as CONTROL_CORE_PAD0_EMMC_CLK_PAD1_EMMC_CMD.EMMC_CMD_WAKEUPENABLE
  [24] C2C_DATAOUT1_INPUTENABLE rw — Input enable value for pad c2c_dataout1
    values as CONTROL_CORE_PAD0_EMMC_CLK_PAD1_EMMC_CMD.EMMC_CMD_INPUTENABLE
  [21] C2C_DATAOUT1_PWRDOWN rw — Power Down setting for pad c2c_dataout1
    values as CONTROL_CORE_PAD0_EMMC_CLK_PAD1_EMMC_CMD.EMMC_CMD_PWRDOWN
  [20] C2C_DATAOUT1_PULLTYPESELECT rw — Pull-Up/Down selection for pad c2c_dataout1
    0=Pull-Down selected; 1=Pull-Up selected
  [19] C2C_DATAOUT1_PULLUDENABLE rw — Pull-Up/Down enable for pad c2c_dataout1
    values as CONTROL_CORE_PAD0_EMMC_CLK_PAD1_EMMC_CMD.EMMC_CMD_PULLUDENABLE
  [18:16] C2C_DATAOUT1_MUXMODE rw — Functional multiplexing selection for pad c2c_dataout1
    6=SEL_GPIO2_57 (Select gpio2_57); 7=SEL_SAFE_MODE_CORE23 (Select safe_mode_core23); 0=SEL_C2C_DATAOUT1 (Reserved); 4=SEL_GPMC_AD9 (Select gpmc_ad9); 5=SEL_HW_DBG17 (Select hw_dbg17); 3=SEL_KBD_COL1 (Select kbd_col1)
  [15] C2C_DATAOUT0_WAKEUPEVENT ro — Pad_x wake-up event status latched in the IO
    values as CONTROL_CORE_PAD0_EMMC_CLK_PAD1_EMMC_CMD.EMMC_CMD_WAKEUPEVENT
  [14] C2C_DATAOUT0_WAKEUPENABLE rw — Input pad wake-up enable
    values as CONTROL_CORE_PAD0_EMMC_CLK_PAD1_EMMC_CMD.EMMC_CMD_WAKEUPENABLE
  [8] C2C_DATAOUT0_INPUTENABLE rw — Input enable value for pad c2c_dataout0
    values as CONTROL_CORE_PAD0_EMMC_CLK_PAD1_EMMC_CMD.EMMC_CMD_INPUTENABLE
  [5] C2C_DATAOUT0_PWRDOWN rw — Power Down setting for pad c2c_dataout0
    values as CONTROL_CORE_PAD0_EMMC_CLK_PAD1_EMMC_CMD.EMMC_CMD_PWRDOWN
  [4] C2C_DATAOUT0_PULLTYPESELECT rw — Pull-Up/Down selection for pad c2c_dataout0
    0=Pull-Down selected; 1=Pull-Up selected
  [3] C2C_DATAOUT0_PULLUDENABLE rw — Pull-Up/Down enable for pad c2c_dataout0
    values as CONTROL_CORE_PAD0_EMMC_CLK_PAD1_EMMC_CMD.EMMC_CMD_PULLUDENABLE
  [2:0] C2C_DATAOUT0_MUXMODE rw — Functional multiplexing selection for pad c2c_dataout0
    6=SEL_GPIO2_56 (Select gpio2_56); 7=SEL_SAFE_MODE_CORE22 (Select safe_mode_core22); 0=SEL_C2C_DATAOUT0 (Reserved); 4=SEL_GPMC_AD8 (Select gpmc_ad8); 5=SEL_HW_DBG16 (Select hw_dbg16); 3=SEL_KBD_COL0 (Select kbd_col0)
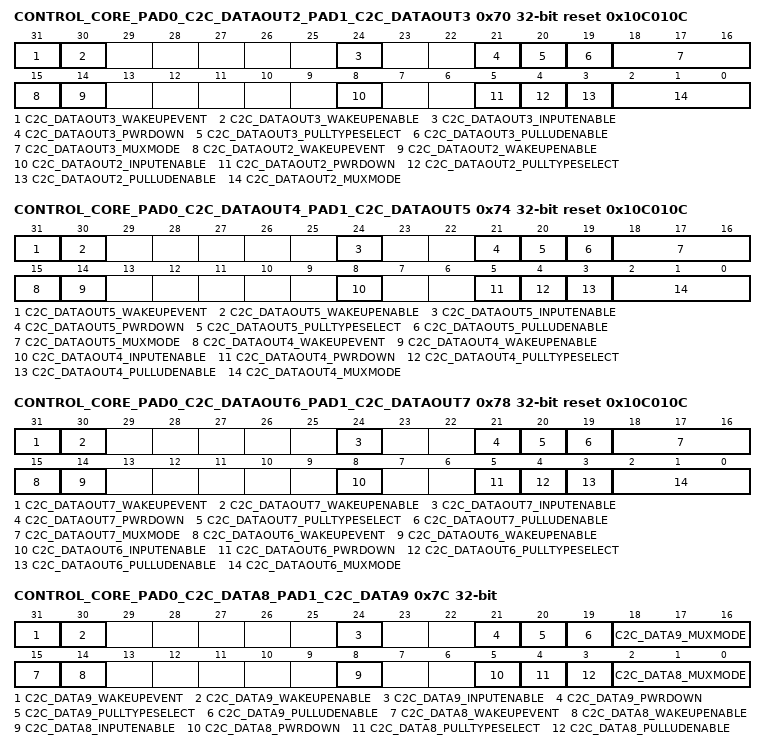
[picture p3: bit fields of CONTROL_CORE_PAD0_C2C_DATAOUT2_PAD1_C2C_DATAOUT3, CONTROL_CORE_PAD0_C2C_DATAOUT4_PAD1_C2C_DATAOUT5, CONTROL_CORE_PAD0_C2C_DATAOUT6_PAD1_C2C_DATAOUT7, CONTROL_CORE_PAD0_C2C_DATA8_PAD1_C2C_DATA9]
0x70 CONTROL_CORE_PAD0_C2C_DATAOUT2_PAD1_C2C_DATAOUT3 reset 0x10C010C — Register control for Pads c2c_dataout2 and c2c_dataout3 Access conditions. Read: unrestricted, Write: unrestricted
  [31] C2C_DATAOUT3_WAKEUPEVENT ro — Pad_x wake-up event status latched in the IO
    values as CONTROL_CORE_PAD0_EMMC_CLK_PAD1_EMMC_CMD.EMMC_CMD_WAKEUPEVENT
  [30] C2C_DATAOUT3_WAKEUPENABLE rw — Input pad wake-up enable
    values as CONTROL_CORE_PAD0_EMMC_CLK_PAD1_EMMC_CMD.EMMC_CMD_WAKEUPENABLE
  [24] C2C_DATAOUT3_INPUTENABLE rw — Input enable value for pad c2c_dataout3
    values as CONTROL_CORE_PAD0_EMMC_CLK_PAD1_EMMC_CMD.EMMC_CMD_INPUTENABLE
  [21] C2C_DATAOUT3_PWRDOWN rw — Power Down setting for pad c2c_dataout3
    values as CONTROL_CORE_PAD0_EMMC_CLK_PAD1_EMMC_CMD.EMMC_CMD_PWRDOWN
  [20] C2C_DATAOUT3_PULLTYPESELECT rw — Pull-Up/Down selection for pad c2c_dataout3
    0=Pull-Down selected; 1=Pull-Up selected
  [19] C2C_DATAOUT3_PULLUDENABLE rw — Pull-Up/Down enable for pad c2c_dataout3
    values as CONTROL_CORE_PAD0_EMMC_CLK_PAD1_EMMC_CMD.EMMC_CMD_PULLUDENABLE
  [18:16] C2C_DATAOUT3_MUXMODE rw — Functional multiplexing selection for pad c2c_dataout3
    6=SEL_GPIO2_59 (Select gpio2_59); 7=SEL_SAFE_MODE_CORE25 (Select safe_mode_core25); 0=SEL_C2C_DATAOUT3 (Reserved); 4=SEL_GPMC_AD11 (Select gpmc_ad11); 5=SEL_HW_DBG19 (Select hw_dbg19); 3=SEL_KBD_COL3 (Select kbd_col3)
  [15] C2C_DATAOUT2_WAKEUPEVENT ro — Pad_x wake-up event status latched in the IO
    values as CONTROL_CORE_PAD0_EMMC_CLK_PAD1_EMMC_CMD.EMMC_CMD_WAKEUPEVENT
  [14] C2C_DATAOUT2_WAKEUPENABLE rw — Input pad wake-up enable
    values as CONTROL_CORE_PAD0_EMMC_CLK_PAD1_EMMC_CMD.EMMC_CMD_WAKEUPENABLE
  [8] C2C_DATAOUT2_INPUTENABLE rw — Input enable value for pad c2c_dataout2
    values as CONTROL_CORE_PAD0_EMMC_CLK_PAD1_EMMC_CMD.EMMC_CMD_INPUTENABLE
  [5] C2C_DATAOUT2_PWRDOWN rw — Power Down setting for pad c2c_dataout2
    values as CONTROL_CORE_PAD0_EMMC_CLK_PAD1_EMMC_CMD.EMMC_CMD_PWRDOWN
  [4] C2C_DATAOUT2_PULLTYPESELECT rw — Pull-Up/Down selection for pad c2c_dataout2
    0=Pull-Down selected; 1=Pull-Up selected
  [3] C2C_DATAOUT2_PULLUDENABLE rw — Pull-Up/Down enable for pad c2c_dataout2
    values as CONTROL_CORE_PAD0_EMMC_CLK_PAD1_EMMC_CMD.EMMC_CMD_PULLUDENABLE
  [2:0] C2C_DATAOUT2_MUXMODE rw — Functional multiplexing selection for pad c2c_dataout2
    6=SEL_GPIO2_58 (Select gpio2_58); 7=SEL_SAFE_MODE_CORE24 (Select safe_mode_core24); 0=SEL_C2C_DATAOUT2 (Reserved); 4=SEL_GPMC_AD10 (Select gpmc_ad10); 5=SEL_HW_DBG18 (Select hw_dbg18); 3=SEL_KBD_COL2 (Select kbd_col2)
0x74 CONTROL_CORE_PAD0_C2C_DATAOUT4_PAD1_C2C_DATAOUT5 reset 0x10C010C — Register control for Pads c2c_dataout4 and c2c_dataout5 Access conditions. Read: unrestricted, Write: unrestricted
  [31] C2C_DATAOUT5_WAKEUPEVENT ro — Pad_x wake-up event status latched in the IO
    values as CONTROL_CORE_PAD0_EMMC_CLK_PAD1_EMMC_CMD.EMMC_CMD_WAKEUPEVENT
  [30] C2C_DATAOUT5_WAKEUPENABLE rw — Input pad wake-up enable
    values as CONTROL_CORE_PAD0_EMMC_CLK_PAD1_EMMC_CMD.EMMC_CMD_WAKEUPENABLE
  [24] C2C_DATAOUT5_INPUTENABLE rw — Input enable value for pad c2c_dataout5
    values as CONTROL_CORE_PAD0_EMMC_CLK_PAD1_EMMC_CMD.EMMC_CMD_INPUTENABLE
  [21] C2C_DATAOUT5_PWRDOWN rw — Power Down setting for pad c2c_dataout5
    values as CONTROL_CORE_PAD0_EMMC_CLK_PAD1_EMMC_CMD.EMMC_CMD_PWRDOWN
  [20] C2C_DATAOUT5_PULLTYPESELECT rw — Pull-Up/Down selection for pad c2c_dataout5
    0=Pull-Down selected; 1=Pull-Up selected
  [19] C2C_DATAOUT5_PULLUDENABLE rw — Pull-Up/Down enable for pad c2c_dataout5
    values as CONTROL_CORE_PAD0_EMMC_CLK_PAD1_EMMC_CMD.EMMC_CMD_PULLUDENABLE
  [18:16] C2C_DATAOUT5_MUXMODE rw — Functional multiplexing selection for pad c2c_dataout5
    6=SEL_GPIO2_61 (Select gpio2_61); 7=SEL_SAFE_MODE_CORE27 (Select safe_mode_core27); 0=SEL_C2C_DATAOUT5 (Reserved); 4=SEL_GPMC_AD13 (Select gpmc_ad13); 5=SEL_HW_DBG21 (Select hw_dbg21); 3=SEL_KBD_COL5 (Select kbd_col5)
  [15] C2C_DATAOUT4_WAKEUPEVENT ro — Pad_x wake-up event status latched in the IO
    values as CONTROL_CORE_PAD0_EMMC_CLK_PAD1_EMMC_CMD.EMMC_CMD_WAKEUPEVENT
  [14] C2C_DATAOUT4_WAKEUPENABLE rw — Input pad wake-up enable
    values as CONTROL_CORE_PAD0_EMMC_CLK_PAD1_EMMC_CMD.EMMC_CMD_WAKEUPENABLE
  [8] C2C_DATAOUT4_INPUTENABLE rw — Input enable value for pad c2c_dataout4
    values as CONTROL_CORE_PAD0_EMMC_CLK_PAD1_EMMC_CMD.EMMC_CMD_INPUTENABLE
  [5] C2C_DATAOUT4_PWRDOWN rw — Power Down setting for pad c2c_dataout4
    values as CONTROL_CORE_PAD0_EMMC_CLK_PAD1_EMMC_CMD.EMMC_CMD_PWRDOWN
  [4] C2C_DATAOUT4_PULLTYPESELECT rw — Pull-Up/Down selection for pad c2c_dataout4
    0=Pull-Down selected; 1=Pull-Up selected
  [3] C2C_DATAOUT4_PULLUDENABLE rw — Pull-Up/Down enable for pad c2c_dataout4
    values as CONTROL_CORE_PAD0_EMMC_CLK_PAD1_EMMC_CMD.EMMC_CMD_PULLUDENABLE
  [2:0] C2C_DATAOUT4_MUXMODE rw — Functional multiplexing selection for pad c2c_dataout4
    6=SEL_GPIO2_60 (Select gpio2_60); 7=SEL_SAFE_MODE_CORE26 (Select safe_mode_core26); 0=SEL_C2C_DATAOUT4 (Reserved); 4=SEL_GPMC_AD12 (Select gpmc_ad12); 5=SEL_HW_DBG20 (Select hw_dbg20); 3=SEL_KBD_COL4 (Select kbd_col4)
0x78 CONTROL_CORE_PAD0_C2C_DATAOUT6_PAD1_C2C_DATAOUT7 reset 0x10C010C — Register control for Pads c2c_dataout6 and c2c_dataout7 Access conditions. Read: unrestricted, Write: unrestricted
  [31] C2C_DATAOUT7_WAKEUPEVENT ro — Pad_x wake-up event status latched in the IO
    values as CONTROL_CORE_PAD0_EMMC_CLK_PAD1_EMMC_CMD.EMMC_CMD_WAKEUPEVENT
  [30] C2C_DATAOUT7_WAKEUPENABLE rw — Input pad wake-up enable
    values as CONTROL_CORE_PAD0_EMMC_CLK_PAD1_EMMC_CMD.EMMC_CMD_WAKEUPENABLE
  [24] C2C_DATAOUT7_INPUTENABLE rw — Input enable value for pad c2c_dataout7
    values as CONTROL_CORE_PAD0_EMMC_CLK_PAD1_EMMC_CMD.EMMC_CMD_INPUTENABLE
  [21] C2C_DATAOUT7_PWRDOWN rw — Power Down setting for pad c2c_dataout7
    values as CONTROL_CORE_PAD0_EMMC_CLK_PAD1_EMMC_CMD.EMMC_CMD_PWRDOWN
  [20] C2C_DATAOUT7_PULLTYPESELECT rw — Pull-Up/Down selection for pad c2c_dataout7
    0=Pull-Down selected; 1=Pull-Up selected
  [19] C2C_DATAOUT7_PULLUDENABLE rw — Pull-Up/Down enable for pad c2c_dataout7
    values as CONTROL_CORE_PAD0_EMMC_CLK_PAD1_EMMC_CMD.EMMC_CMD_PULLUDENABLE
  [18:16] C2C_DATAOUT7_MUXMODE rw — Functional multiplexing selection for pad c2c_dataout7
    6=SEL_GPIO2_63 (Select gpio2_63); 7=SEL_SAFE_MODE_CORE29 (Select safe_mode_core29); 0=SEL_C2C_DATAOUT7 (Reserved); 4=SEL_GPMC_AD15 (Select gpmc_ad15); 5=SEL_HW_DBG23 (Select hw_dbg23); 3=SEL_KBD_COL7 (Select kbd_col7)
  [15] C2C_DATAOUT6_WAKEUPEVENT ro — Pad_x wake-up event status latched in the IO
    values as CONTROL_CORE_PAD0_EMMC_CLK_PAD1_EMMC_CMD.EMMC_CMD_WAKEUPEVENT
  [14] C2C_DATAOUT6_WAKEUPENABLE rw — Input pad wake-up enable
    values as CONTROL_CORE_PAD0_EMMC_CLK_PAD1_EMMC_CMD.EMMC_CMD_WAKEUPENABLE
  [8] C2C_DATAOUT6_INPUTENABLE rw — Input enable value for pad c2c_dataout6
    values as CONTROL_CORE_PAD0_EMMC_CLK_PAD1_EMMC_CMD.EMMC_CMD_INPUTENABLE
  [5] C2C_DATAOUT6_PWRDOWN rw — Power Down setting for pad c2c_dataout6
    values as CONTROL_CORE_PAD0_EMMC_CLK_PAD1_EMMC_CMD.EMMC_CMD_PWRDOWN
  [4] C2C_DATAOUT6_PULLTYPESELECT rw — Pull-Up/Down selection for pad c2c_dataout6
    0=Pull-Down selected; 1=Pull-Up selected
  [3] C2C_DATAOUT6_PULLUDENABLE rw — Pull-Up/Down enable for pad c2c_dataout6
    values as CONTROL_CORE_PAD0_EMMC_CLK_PAD1_EMMC_CMD.EMMC_CMD_PULLUDENABLE
  [2:0] C2C_DATAOUT6_MUXMODE rw — Functional multiplexing selection for pad c2c_dataout6
    6=SEL_GPIO2_62 (Select gpio2_62); 7=SEL_SAFE_MODE_CORE28 (Select safe_mode_core28); 0=SEL_C2C_DATAOUT6 (Reserved); 4=SEL_GPMC_AD14 (Select gpmc_ad14); 5=SEL_HW_DBG22 (Select hw_dbg22); 3=SEL_KBD_COL6 (Select kbd_col6)
0x7C CONTROL_CORE_PAD0_C2C_DATA8_PAD1_C2C_DATA9 — Register control for Pads c2c_data8 and c2c_data9 Access conditions. Read: unrestricted, Write: unrestricted
  [31] C2C_DATA9_WAKEUPEVENT ro — Pad_x wake-up event status latched in the IO
    values as CONTROL_CORE_PAD0_EMMC_CLK_PAD1_EMMC_CMD.EMMC_CMD_WAKEUPEVENT
  [30] C2C_DATA9_WAKEUPENABLE rw — Input pad wake-up enable
    values as CONTROL_CORE_PAD0_EMMC_CLK_PAD1_EMMC_CMD.EMMC_CMD_WAKEUPENABLE
  [24] C2C_DATA9_INPUTENABLE rw — Input enable value for pad c2c_data9
    values as CONTROL_CORE_PAD0_EMMC_CLK_PAD1_EMMC_CMD.EMMC_CMD_INPUTENABLE
  [21] C2C_DATA9_PWRDOWN rw — Power Down setting for pad c2c_data9
    values as CONTROL_CORE_PAD0_EMMC_CLK_PAD1_EMMC_CMD.EMMC_CMD_PWRDOWN
  [20] C2C_DATA9_PULLTYPESELECT rw — Pull-Up/Down selection for pad c2c_data9
    0=Pull-Down selected; 1=Pull-Up selected
  [19] C2C_DATA9_PULLUDENABLE rw — Pull-Up/Down enable for pad c2c_data9
    values as CONTROL_CORE_PAD0_EMMC_CLK_PAD1_EMMC_CMD.EMMC_CMD_PULLUDENABLE
  [18:16] C2C_DATA9_MUXMODE rw — Functional multiplexing selection for pad c2c_data9
    0=SEL_C2C_DATA9 (Reserved); 6=SEL_GPIO4_114 (Select gpio4_114); 4=SEL_GPMC_A17 (Select gpmc_a17); 7=SEL_SAFE_MODE_CORE31 (Select safe_mode_core31); 5=SEL_HW_DBG25 (Select hw_dbg25)
  [15] C2C_DATA8_WAKEUPEVENT ro — Pad_x wake-up event status latched in the IO
    values as CONTROL_CORE_PAD0_EMMC_CLK_PAD1_EMMC_CMD.EMMC_CMD_WAKEUPEVENT
  [14] C2C_DATA8_WAKEUPENABLE rw — Input pad wake-up enable
    values as CONTROL_CORE_PAD0_EMMC_CLK_PAD1_EMMC_CMD.EMMC_CMD_WAKEUPENABLE
  [8] C2C_DATA8_INPUTENABLE rw — Input enable value for pad c2c_data8
    values as CONTROL_CORE_PAD0_EMMC_CLK_PAD1_EMMC_CMD.EMMC_CMD_INPUTENABLE
  [5] C2C_DATA8_PWRDOWN rw — Power Down setting for pad c2c_data8
    values as CONTROL_CORE_PAD0_EMMC_CLK_PAD1_EMMC_CMD.EMMC_CMD_PWRDOWN
  [4] C2C_DATA8_PULLTYPESELECT rw — Pull-Up/Down selection for pad c2c_data8
    0=Pull-Down selected; 1=Pull-Up selected
  [3] C2C_DATA8_PULLUDENABLE rw — Pull-Up/Down enable for pad c2c_data8
    values as CONTROL_CORE_PAD0_EMMC_CLK_PAD1_EMMC_CMD.EMMC_CMD_PULLUDENABLE
  [2:0] C2C_DATA8_MUXMODE rw — Functional multiplexing selection for pad c2c_data8
    0=SEL_C2C_DATA8 (Reserved); 6=SEL_GPIO4_113 (Select gpio4_113); 4=SEL_GPMC_A16 (Select gpmc_a16); 7=SEL_SAFE_MODE_CORE30 (Select safe_mode_core30); 5=SEL_HW_DBG24 (Select hw_dbg24)
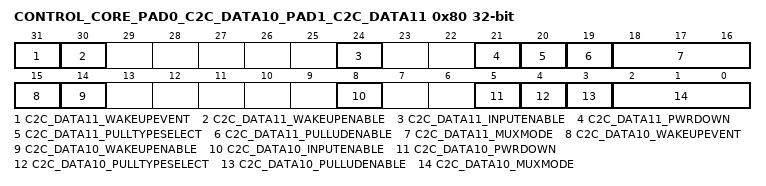
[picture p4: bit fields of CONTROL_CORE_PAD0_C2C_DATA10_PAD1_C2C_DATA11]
0x80 CONTROL_CORE_PAD0_C2C_DATA10_PAD1_C2C_DATA11 — Register control for Pads c2c_data10 and c2c_data11 Access conditions. Read: unrestricted, Write: unrestricted
  [31] C2C_DATA11_WAKEUPEVENT ro — Pad_x wake-up event status latched in the IO
    values as CONTROL_CORE_PAD0_EMMC_CLK_PAD1_EMMC_CMD.EMMC_CMD_WAKEUPEVENT
  [30] C2C_DATA11_WAKEUPENABLE rw — Input pad wake-up enable
    values as CONTROL_CORE_PAD0_EMMC_CLK_PAD1_EMMC_CMD.EMMC_CMD_WAKEUPENABLE
  [24] C2C_DATA11_INPUTENABLE rw — Input enable value for pad c2c_data11
    values as CONTROL_CORE_PAD0_EMMC_CLK_PAD1_EMMC_CMD.EMMC_CMD_INPUTENABLE
  [21] C2C_DATA11_PWRDOWN rw — Power Down setting for pad c2c_data11
    values as CONTROL_CORE_PAD0_EMMC_CLK_PAD1_EMMC_CMD.EMMC_CMD_PWRDOWN
  [20] C2C_DATA11_PULLTYPESELECT rw — Pull-Up/Down selection for pad c2c_data11
    0=Pull-Down selected; 1=Pull-Up selected
  [19] C2C_DATA11_PULLUDENABLE rw — Pull-Up/Down enable for pad c2c_data11
    values as CONTROL_CORE_PAD0_EMMC_CLK_PAD1_EMMC_CMD.EMMC_CMD_PULLUDENABLE
  [18:16] C2C_DATA11_MUXMODE rw — Functional multiplexing selection for pad c2c_data11
    0=SEL_C2C_DATA11 (Reserved); 6=SEL_GPIO4_116 (Select gpio4_116); 4=SEL_GPMC_A19 (Select gpmc_a19); 7=SEL_SAFE_MODE_CORE33 (Select safe_mode_core33); 5=SEL_HW_DBG27 (Select hw_dbg27)
  [15] C2C_DATA10_WAKEUPEVENT ro — Pad_x wake-up event status latched in the IO
    values as CONTROL_CORE_PAD0_EMMC_CLK_PAD1_EMMC_CMD.EMMC_CMD_WAKEUPEVENT
  [14] C2C_DATA10_WAKEUPENABLE rw — Input pad wake-up enable
    values as CONTROL_CORE_PAD0_EMMC_CLK_PAD1_EMMC_CMD.EMMC_CMD_WAKEUPENABLE
  [8] C2C_DATA10_INPUTENABLE rw — Input enable value for pad c2c_data10
    values as CONTROL_CORE_PAD0_EMMC_CLK_PAD1_EMMC_CMD.EMMC_CMD_INPUTENABLE
  [5] C2C_DATA10_PWRDOWN rw — Power Down setting for pad c2c_data10
    values as CONTROL_CORE_PAD0_EMMC_CLK_PAD1_EMMC_CMD.EMMC_CMD_PWRDOWN
  [4] C2C_DATA10_PULLTYPESELECT rw — Pull-Up/Down selection for pad c2c_data10
    0=Pull-Down selected; 1=Pull-Up selected
  [3] C2C_DATA10_PULLUDENABLE rw — Pull-Up/Down enable for pad c2c_data10
    values as CONTROL_CORE_PAD0_EMMC_CLK_PAD1_EMMC_CMD.EMMC_CMD_PULLUDENABLE
  [2:0] C2C_DATA10_MUXMODE rw — Functional multiplexing selection for pad c2c_data10
    0=SEL_C2C_DATA10 (Reserved); 6=SEL_GPIO4_115 (Select gpio4_115); 4=SEL_GPMC_A18 (Select gpmc_a18); 7=SEL_SAFE_MODE_CORE32 (Select safe_mode_core32); 5=SEL_HW_DBG26 (Select hw_dbg26)
